# STM32WBA23 register map
File version: 1.0
CPU: CM33 r0p1, little endian, MPU, FPU, 4 interrupt priority bits
Registers are 32-bit, read-write, reset 0x0 unless marked. A register's access mark holds for its fields unless they carry their own. Offsets are from the block's base; [hi:lo] are bit positions; {n}, {i} and the like mark numbered series; 'fields as' and 'values as' point back to an identical list.

## FLASH — FLASH address block description
Base 0x40022000
Same registers: SEC_FLASH 0x50022000
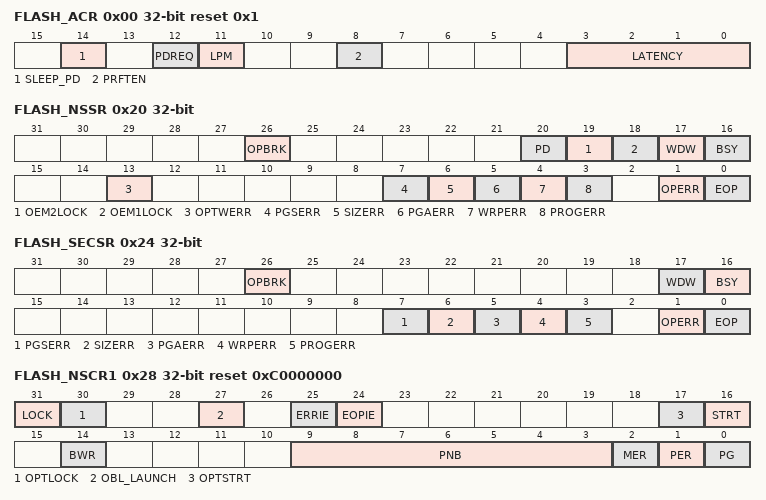
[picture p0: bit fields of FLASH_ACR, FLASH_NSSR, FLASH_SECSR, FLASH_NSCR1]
0x00 FLASH_ACR reset 0x1 — FLASH access control register
  [14] SLEEP_PD — Flash memory power-down mode during Sleep mode
    0=Flash in idle mode during Sleep mode; 1=Flash in power-down mode during Sleep mode
  [12] PDREQ — Flash power-down mode request
    0=No request for flash to enter power-down mode; 1=Flash requested to enter power-down mode
  [11] LPM — Low-power read mode
    0=Flash not in low-power read mode; 1=Flash in low-power read mode
  [8] PRFTEN — Prefetch enable
    0=Prefetch disabled; 1=Prefetch enabled
  [3:0] LATENCY
    0=Zero wait state; 1=One wait state; 2=Two wait states; 15=Fifteen wait states
0x08 FLASH_NSKEYR wo — FLASH key register
  [31:0] NSKEY — Flash memory nonsecure key
0x0C FLASH_SECKEYR wo — FLASH secure key register
  [31:0] SECKEY — Flash memory secure key
0x10 FLASH_OPTKEYR wo — FLASH option key register
  [31:0] OPTKEY — Option byte key
0x18 FLASH_PDKEYR wo — FLASH power-down key register
  [31:0] PDKEY1 — Flash power-down key
0x20 FLASH_NSSR (reset mask 0xFFF0FFFF) — FLASH status register
  [26] OPBRK — Nonsecure flash operation aborted
  [20] PD ro — Flash in power-down mode
  [19] OEM2LOCK ro — OEM2 key RDP lock
  [18] OEM1LOCK ro — OEM1 key RDP lock
  [17] WDW ro — Nonsecure wait data to write
  [16] BSY ro — Nonsecure busy
  [13] OPTWERR — Option write error
  [7] PGSERR — Nonsecure programming sequence error
  [6] SIZERR — Nonsecure size error
  [5] PGAERR — Nonsecure programming alignment error
  [4] WRPERR — Nonsecure write protection error
  [3] PROGERR — Nonsecure programming error
  [1] OPERR — Nonsecure operation error
  [0] EOP — Nonsecure end of operation
0x24 FLASH_SECSR — FLASH secure status register
  [26] OPBRK — Secure flash operation aborted
  [17] WDW ro — Secure wait data to write
  [16] BSY ro — Secure busy
  [7] PGSERR — Secure programming sequence error
  [6] SIZERR — Secure size error
  [5] PGAERR — Secure programming alignment error
  [4] WRPERR — Secure write protection error
  [3] PROGERR — Secure programming error
  [1] OPERR — Secure operation error
  [0] EOP — Secure end of operation
0x28 FLASH_NSCR1 reset 0xC0000000 — FLASH control register
  [31] LOCK — Nonsecure lock
  [30] OPTLOCK — Option lock
  [27] OBL_LAUNCH — Force the option byte loading
    0=Option byte loading complete; 1=Option byte loading requested
  [25] ERRIE — Nonsecure error interrupt enable
    0=Nonsecure OPERR error interrupt disabled; 1=Nonsecure OPERR error interrupt enabled
  [24] EOPIE — Nonsecure end of operation interrupt enable
    0=Nonsecure EOP Interrupt disabled; 1=Nonsecure EOP Interrupt enabled
  [17] OPTSTRT — Options modification start
  [16] STRT — Nonsecure operation start
  [14] BWR — Nonsecure burst write programming mode
  [9:3] PNB — Nonsecure page number selection
    0=page 0; 1=page 1; 127=page 127
  [2] MER — Nonsecure flash mass erase
  [1] PER — Nonsecure page erase
    0=Nonsecure page erase disabled; 1=Nonsecure page erase enabled
  [0] PG — Nonsecure programming
    0=Nonsecure flash programming disabled; 1=Nonsecure flash programming enabled
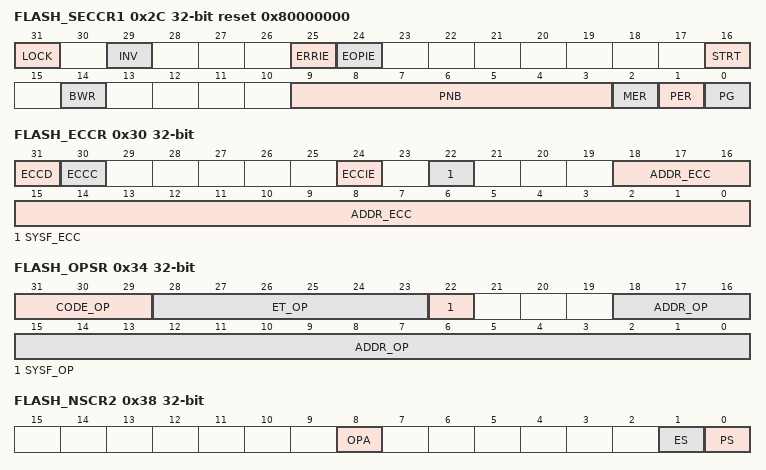
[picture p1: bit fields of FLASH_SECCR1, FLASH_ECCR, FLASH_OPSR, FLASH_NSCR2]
0x2C FLASH_SECCR1 reset 0x80000000 — FLASH secure control register
  [31] LOCK — Secure lock
  [29] INV — Flash memory security state invert
  [25] ERRIE — Secure error interrupt enable
    0=Secure OPERR error interrupt disabled; 1=Secure OPERR error interrupt enabled
  [24] EOPIE — Secure End of operation interrupt enable
    0=Secure EOP Interrupt disabled; 1=Secure EOP Interrupt enabled
  [16] STRT — Secure start
  [14] BWR — Secure burst write programming mode
  [9:3] PNB — Secure page number selection
    0=page 0; 1=page 1; 127=page 127
  [2] MER — Secure flash mass erase
  [1] PER — Secure page erase
    0=Secure page erase disabled; 1=Secure page erase enabled
  [0] PG — Secure programming
    0=Secure flash programming disabled; 1=Secure flash programming enabled
0x30 FLASH_ECCR — FLASH ECC register
  [31] ECCD — ECC detection
  [30] ECCC — ECC correction
  [24] ECCIE — ECC correction interrupt enable
    0=ECCC interrupt disabled; 1=ECCC interrupt enabled
  [22] SYSF_ECC ro — System flash memory ECC fail
  [18:0] ADDR_ECC ro — ECC fail address
0x34 FLASH_OPSR ro reset not defined — FLASH operation status register
  [31:29] CODE_OP — Flash memory operation code
    0=No flash operation interrupted; 1=Single write operation interrupted; 2=Burst write operation interrupted; 3=Page erase operation interrupted; 5=Mass erase operation interrupted; 6=Option change operation interrupted
  [28:23] ET_OP — Elapsed erase time or burst programmed double-words before interruption
  [22] SYSF_OP — Operation in system flash memory interrupted
  [18:0] ADDR_OP — Interrupted operation address
0x38 FLASH_NSCR2 — FLASH control 2 register
  [8] OPA — Flash operation abort
    0=no effect; 1=writing 1 when a flash nonsecure operation is ongoing will abort the ongoing flash nonsecure operation
  [1] ES — Erase suspend request
    0=erase suspend disabled; 1=erase suspend requested (enabled)
  [0] PS — Program suspend request
    0=program suspend disabled; 1=program suspend requested (enabled)
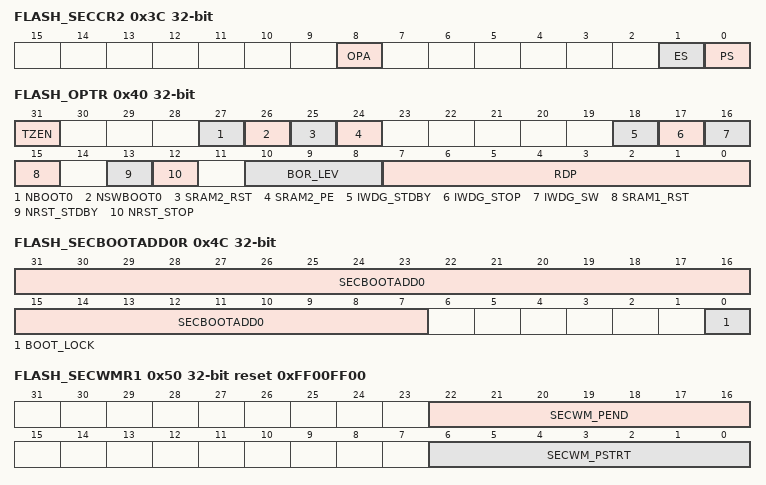
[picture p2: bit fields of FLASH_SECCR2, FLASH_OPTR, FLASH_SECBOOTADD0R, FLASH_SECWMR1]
0x3C FLASH_SECCR2 — FLASH secure control 2 register
  [8] OPA — Flash operation abort
    0=no effect; 1=writing 1 when a flash secure or nonsecure operation is ongoing will abort the ongoing secure or nonsecure flash operation
  [1] ES — Erase suspend request
    values as FLASH_NSCR2.ES
  [0] PS — Program suspend request
    values as FLASH_NSCR2.PS
0x40 FLASH_OPTR reset not defined — FLASH option register
  [31] TZEN — Global TrustZone security enable
    0=Global TrustZone security disabled; 1=Global TrustZone security enabled
  [27] NBOOT0 — NBOOT0 option bit
    0=NBOOT0 = 0; 1=NBOOT0 = 1
  [26] NSWBOOT0 — Software BOOT0
    0=BOOT0 taken from the option bit NBOOT0; 1=BOOT0 taken from PH3/BOOT0 pin
  [25] SRAM2_RST — SRAM2 erase upon system reset
    0=SRAM2 erased when a system reset occurs; 1=SRAM2 not erased when a system reset occurs
  [24] SRAM2_PE — SRAM2 parity check disable
    0=SRAM2 parity check enabled; 1=SRAM2 parity check disabled
  [18] IWDG_STDBY — Independent watchdog counter freeze in Standby mode
    0=Independent watchdog counter frozen in Standby mode; 1=Independent watchdog counter running in Standby mode
  [17] IWDG_STOP — Independent watchdog counter freeze in Stop mode
    0=Independent watchdog counter frozen in Stop mode; 1=Independent watchdog counter running in Stop mode
  [16] IWDG_SW — Independent watchdog enable selection
    0=Hardware mode, independent watchdog started automatically be hardware on reset selected; 1=Software mode, independent watchdog started by software command selected
  [15] SRAM1_RST — SRAM1 erase upon system reset
    0=SRAM1erased when a system reset occurs; 1=SRAM1 not erased when a system reset occurs
  [13] NRST_STDBY — Reset generation in Standby mode
    0=Reset generated when entering the Standby mode; 1=No reset generated when entering the Standby mode
  [12] NRST_STOP — Reset generation in Stop mode
    0=Reset generated when entering the Stop mode; 1=No reset generated when entering the Stop mode
  [10:8] BOR_LEV — BOR reset level
    0=BOR level 0 (reset level threshold around 1; {v}=BOR level {v} (reset level threshold around 2 (v=1..4)
  [7:0] RDP — Readout protection level
    170=Level 0 (readout protection not active); 85=Level 0; 204=Level 2 (chip readout protection active)
0x44 FLASH_NSBOOTADD0R reset 0xF (reset mask 0xF) — FLASH boot address 0 register
  [31:7] NSBOOTADD0 — Nonsecure boot base address 0
0x48 FLASH_NSBOOTADD1R reset 0xF (reset mask 0xF) — FLASH boot address 1 register
  [31:7] NSBOOTADD1 — Nonsecure boot address 1
0x4C FLASH_SECBOOTADD0R reset not defined — FLASH secure boot address 0 register
  [31:7] SECBOOTADD0 — Secure boot base address 0
  [0] BOOT_LOCK
0x50 FLASH_SECWMR1 reset 0xFF00FF00 (reset mask 0xFF00FF00) — FLASH secure watermark register 1
  [22:16] SECWM_PEND — End page of secure area
  [6:0] SECWM_PSTRT — Start page of secure area
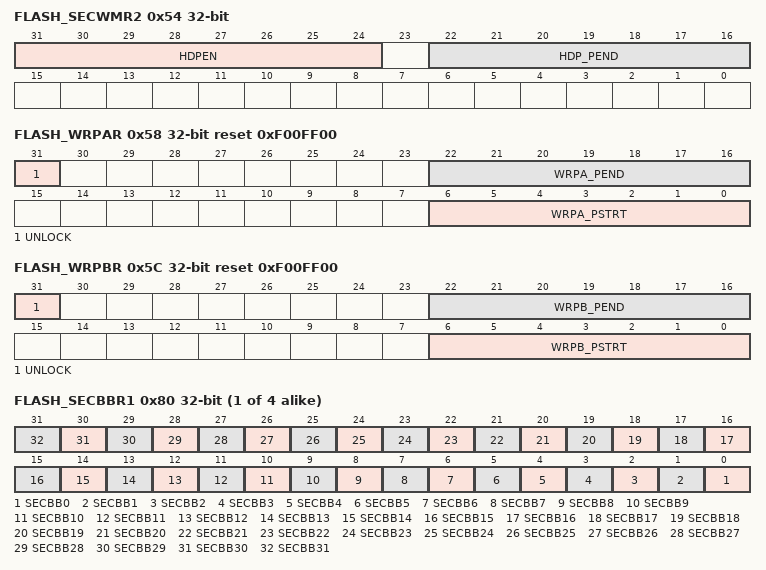
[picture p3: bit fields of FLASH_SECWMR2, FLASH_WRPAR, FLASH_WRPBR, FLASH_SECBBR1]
0x54 FLASH_SECWMR2 reset not defined — FLASH secure watermark register 2
  [31:24] HDPEN — Secure Hide protection area enable
    180=No secure HDP area
  [22:16] HDP_PEND — End page of secure hide protection area
0x58 FLASH_WRPAR reset 0xF00FF00 (reset mask 0xF00FF00) — FLASH WRP area A address register
  [31] UNLOCK — WPR area A unlock
    0=WRPA start and end pages locked; 1=WRPA start and end pages unlocked
  [22:16] WRPA_PEND — WPR area A end page
  [6:0] WRPA_PSTRT — WPR area A start page
0x5C FLASH_WRPBR reset 0xF00FF00 (reset mask 0xF00FF00) — FLASH WRP area B address register
  [31] UNLOCK — WPR area B unlock
    0=WRPB start and end pages locked; 1=WRPB start and end pages unlocked
  [22:16] WRPB_PEND — WRP area B end page
  [6:0] WRPB_PSTRT — WRP area B start page
{0x7C+4i} FLASH_SECBBR{i} (i=1..4) — FLASH secure block based register {i}
  [all] fields
    0=Page (32 x (x - 1) + y) in flash not block-based secure; 1=Page (32 x (x - 1) + y) in flash block-based secure
  [n] SECBB{n} (n=0..31) — page secure/nonsecure attribution
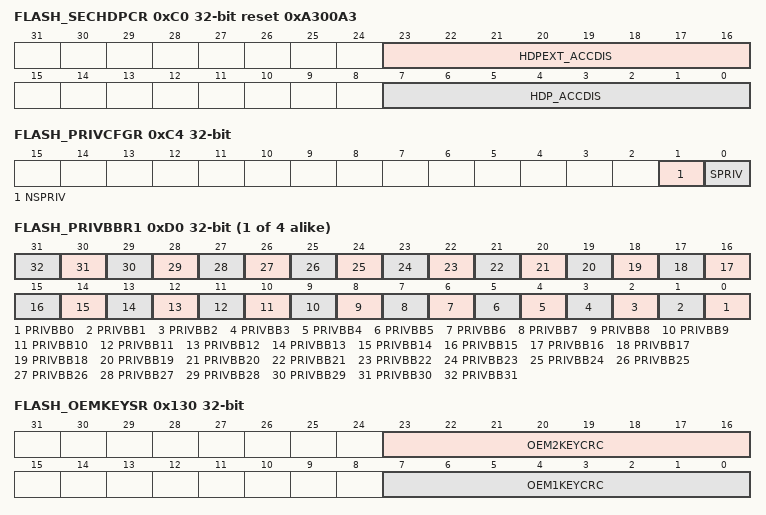
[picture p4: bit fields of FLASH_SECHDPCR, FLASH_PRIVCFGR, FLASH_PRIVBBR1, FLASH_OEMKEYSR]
0xC0 FLASH_SECHDPCR reset 0xA300A3 — FLASH secure HDP control register
  [23:16] HDPEXT_ACCDIS — Secure HDP extension area access disable
    163=Access to secure HDP extension area granted; 92=Access to secure HDP area and HDP extension area denied, and HDP_PEXT increment allowed at any time
  [7:0] HDP_ACCDIS — Secure HDP area access disable
    163=Access to secure HDP area granted
0xC4 FLASH_PRIVCFGR — FLASH privilege configuration register
  [1] NSPRIV — Privileged protection for nonsecure registers
    0=Nonsecure flash registers can be read and written by privileged or unprivileged access; 1=Nonsecure flash registers can be read and written by privileged access only
  [0] SPRIV — Privileged protection for secure registers
    0=Secure flash registers can be read and written by privileged or unprivileged access; 1=Secure flash registers can be read and written by privileged access only
0xC8 FLASH_SECHDPEXTR — FLASH secure HDP extension register
  [6:0] HDP_PEXT — Number of secure HDP extension area pages.
{0xCC+4i} FLASH_PRIVBBR{i} (i=1..4) — FLASH privilege block based register {i}
  [all] fields
    0=Page (32 x (x - 1) + y) in flash accessible by unprivileged access; 1=Page (32 x (x - 1) + y) in flash only accessible by privileged access
  [n] PRIVBB{n} (n=0..31) — page privileged/unprivileged attribution
0x110 FLASH_OEM1KEYR1 wo — FLASH OEM1 key register 1
  [31:0] OEM1KEY — OEM1 key least significant bytes
0x114 FLASH_OEM1KEYR2 wo — FLASH OEM1 key register 2
  [31:0] OEM1KEY — OEM1 key middle bytes
0x114 FLASH_OEM1KEYR4 wo (alternate view of FLASH_OEM1KEYR2) — FLASH OEM1 key register 4
  [31:0] OEM1KEY — OEM1 key most significant bytes
0x118 FLASH_OEM1KEYR3 wo — FLASH OEM1 key register 3
  [31:0] OEM1KEY — OEM1 key middle bytes
0x120 FLASH_OEM2KEYR1 wo — FLASH OEM2 key register 1
  [31:0] OEM2KEY — OEM2 key least significant bytes
0x124 FLASH_OEM2KEYR2 wo — FLASH OEM2 key register 2
  [31:0] OEM2KEY — OEM2 key middle bytes
0x128 FLASH_OEM2KEYR3 wo — FLASH OEM2 key register 3
  [31:0] OEM2KEY — OEM2 key middle bytes
0x12C FLASH_OEM2KEYR4 wo — FLASH OEM2 key register 4
  [31:0] OEM2KEY — OEM2 key most significant bytes
0x130 FLASH_OEMKEYSR ro (reset mask 0xFF00FF00) — FLASH OEM key status register
  [23:16] OEM2KEYCRC — OEM2 key CRC value
  [7:0] OEM1KEYCRC — OEM1 key CRC value

## Notices in the file
Copyright (c) 2026 STMicroelectronics.
SPDX-License-Identifier: Apache-2.0
Licensed under the Apache License, Version 2.0 (the "License");
you may not use this file except in compliance with the License.
You may obtain a copy of the License at
http://www.apache.org/licenses/LICENSE-2.0
Unless required by applicable law or agreed to in writing, software
distributed under the License is distributed on an "AS IS" BASIS,
WITHOUT WARRANTIES OR CONDITIONS OF ANY KIND, either express or implied.
See the License for the specific language governing permissions and
limitations under the License.
